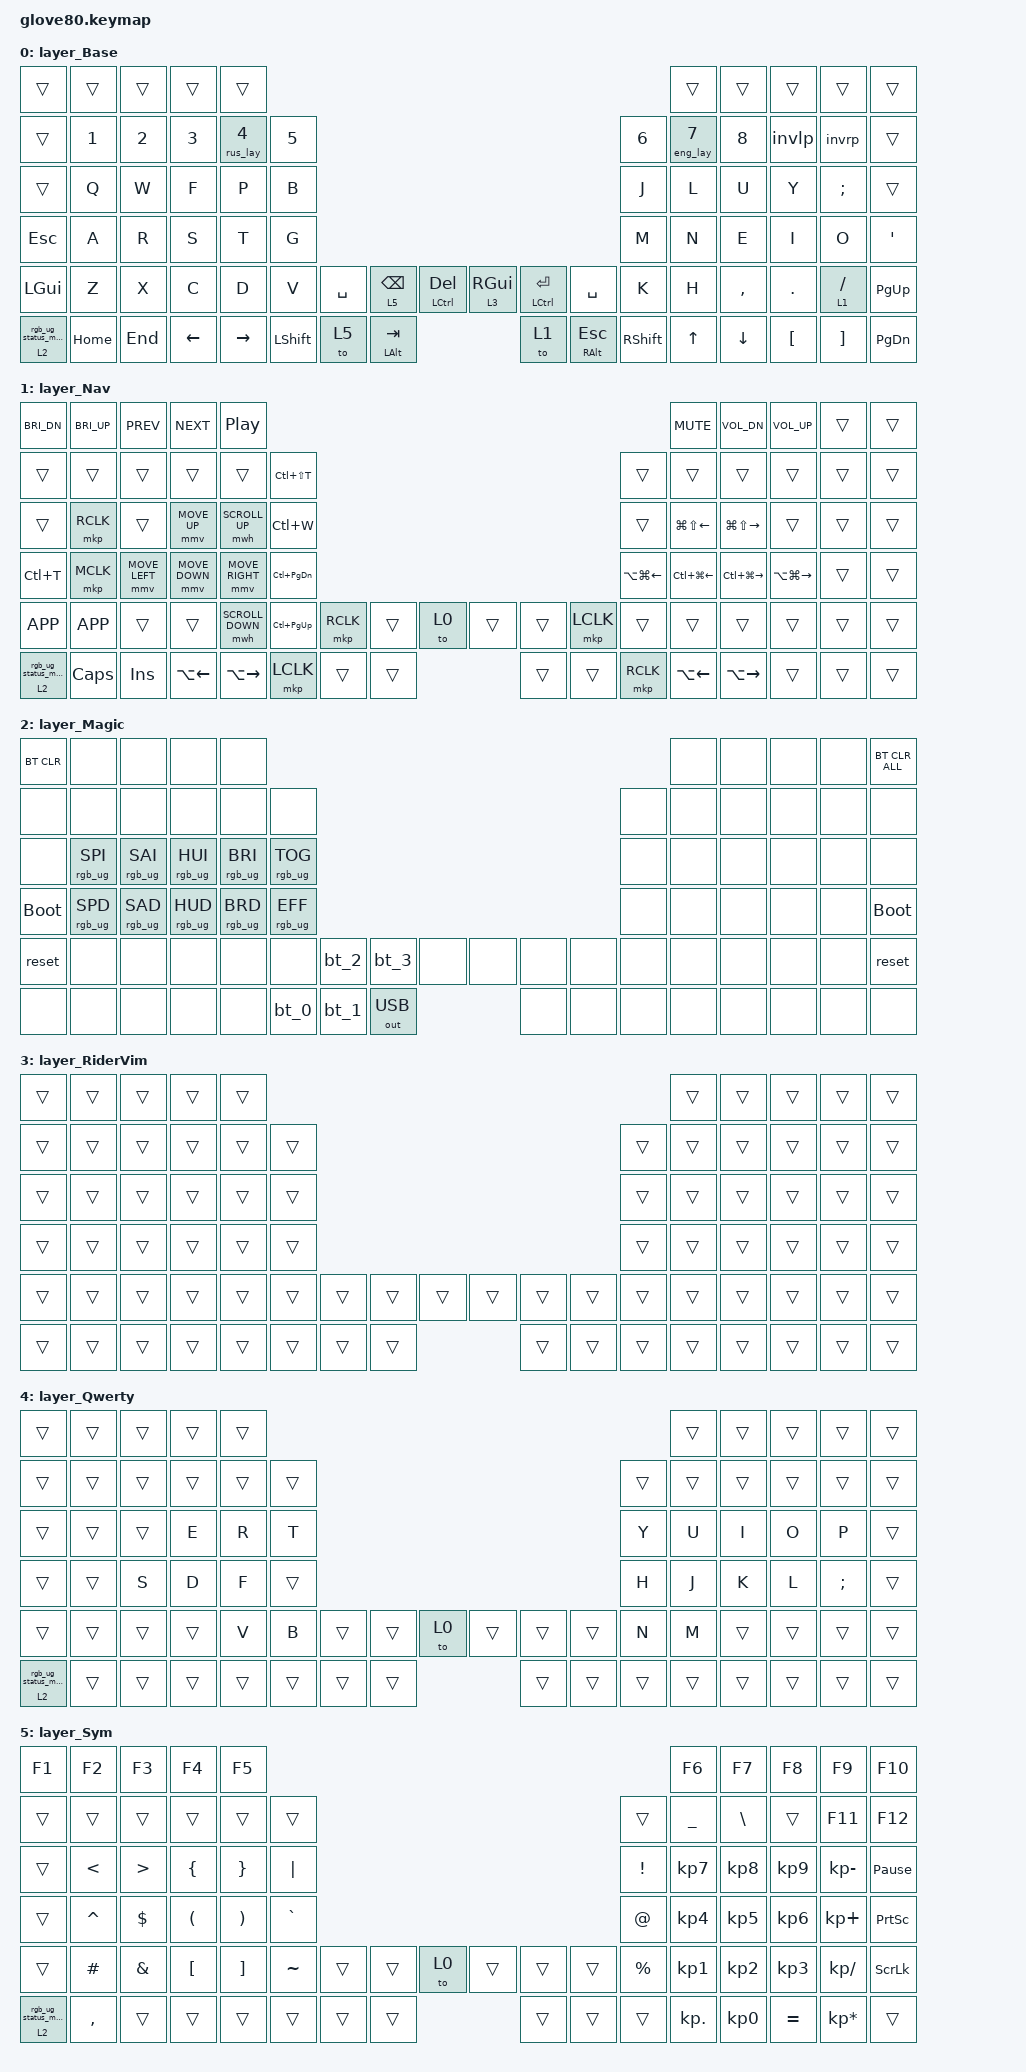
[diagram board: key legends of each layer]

/*
 * Copyright (c) 2020 The ZMK Contributors
 * Copyright (c) 2022 Innaworks Development Limited, trading as MoErgo
 *
 * SPDX-License-Identifier: MIT
 */


/* THIS FILE WAS GENERATED BY GLOVE80 LAYOUT EDITOR
 *
 * This file was generated automatically. You may or may not want to
 * edit it directly.
 */

#include <behaviors.dtsi>
/* Include all behaviour includes needed by system behaviors/macros */
#include <dt-bindings/zmk/outputs.h>

/* Include behaviour includes needed by key binds - automatically generated */
#include <dt-bindings/zmk/keys.h>
#include <dt-bindings/zmk/bt.h>
#include <dt-bindings/zmk/rgb.h>
#include <dt-bindings/zmk/outputs.h>
#include <dt-bindings/zmk/mouse.h>

&mmv {
    acceleration-exponent = <1>;      // 1
    time-to-max-speed-ms = <400>;     // 300
    delay-ms = <0>;                   // 0
};

&mwh {
    acceleration-exponent = <1>;      // 0
    time-to-max-speed-ms = <40>;      // 300
    delay-ms = <0>;                   // 0
};

#define U_MOUSE_MOVE_MAX 1200       // 600
#define U_MOUSE_SCROLL_MAX 20       // 10

#undef MOVE_UP
#undef MOVE_DOWN
#undef MOVE_LEFT
#undef MOVE_RIGHT
#define MOVE_UP MOVE_VERT(-U_MOUSE_MOVE_MAX)
#define MOVE_DOWN MOVE_VERT(U_MOUSE_MOVE_MAX)
#define MOVE_LEFT MOVE_HOR(-U_MOUSE_MOVE_MAX)
#define MOVE_RIGHT MOVE_HOR(U_MOUSE_MOVE_MAX)

#undef SCROLL_UP
#undef SCROLL_DOWN
#undef SCROLL_LEFT
#undef SCROLL_RIGHT
#define SCROLL_UP SCROLL_VERT(U_MOUSE_SCROLL_MAX)
#define SCROLL_DOWN SCROLL_VERT(-U_MOUSE_SCROLL_MAX)
#define SCROLL_LEFT SCROLL_HOR(-U_MOUSE_SCROLL_MAX)
#define SCROLL_RIGHT SCROLL_HOR(U_MOUSE_SCROLL_MAX)

/ {
    /* Glove80 system behavior & macros */
    behaviors {
        // For the "layer" key, it'd nice to be able to use it as either a shift or a toggle.
        // Configure it as a tap dance, so the first tap (or hold) is a &mo and the second tap is a &to
        lower: tap_dance_0 {
            compatible = "zmk,behavior-tap-dance";
            label = "LAYER_TAP_DANCE";
            #binding-cells = <0>;
            tapping-term-ms = <200>;
            bindings = <&mo 1>, <&to 1>;
        };
    };

    macros {
        rgb_ug_status_macro: rgb_ug_status_macro_0 {
            label = "RGB_UG_STATUS";
            compatible = "zmk,behavior-macro";
            #binding-cells = <0>;
            bindings
                = <&rgb_ug RGB_STATUS>;
        };
    };

    macros {
        bt_0: bt_profile_macro_0 {
            label = "BT_0";
            compatible = "zmk,behavior-macro";
            #binding-cells = <0>;
            bindings
                = <&out OUT_BLE>,
                  <&bt BT_SEL 0>;
        };
    };

    macros {
        bt_1: bt_profile_macro_1 {
            label = "BT_1";
            compatible = "zmk,behavior-macro";
            #binding-cells = <0>;
            bindings
                = <&out OUT_BLE>,
                  <&bt BT_SEL 1>;
        };
    };

    macros {
        bt_2: bt_profile_macro_2 {
            label = "BT_2";
            compatible = "zmk,behavior-macro";
            #binding-cells = <0>;
            bindings
                = <&out OUT_BLE>,
                  <&bt BT_SEL 2>;
        };
    };

    macros {
        bt_3: bt_profile_macro_3 {
            label = "BT_3";
            compatible = "zmk,behavior-macro";
            #binding-cells = <0>;
            bindings
                = <&out OUT_BLE>,
                  <&bt BT_SEL 3>;
        };
    };

    magic: magic_hold_tap {
        compatible = "zmk,behavior-hold-tap";
        label = "MAGIC_HOLD_TAP";
        #binding-cells = <2>;
        flavor = "tap-preferred";
        tapping-term-ms = <200>;
        bindings = <&mo>, <&rgb_ug_status_macro>;
    };

    /* Custom Defined Behaviors */
behaviors {
    invlp: invert_leftpar {
        compatible = "zmk,behavior-mod-morph";
        label = "INVERT_LEFTP";
        #binding-cells = <0>;
        bindings = <&kp LEFT_PARENTHESIS>, <&kp KP_N9>;
        mods = <(MOD_LSFT|MOD_RSFT)>;
    };
    invrp: invert_rightpar {
        compatible = "zmk,behavior-mod-morph";
        label = "INVERT_RIGHTP";
        #binding-cells = <0>;
        bindings = <&kp RIGHT_PARENTHESIS>, <&kp KP_N0>;
        mods = <(MOD_LSFT|MOD_RSFT)>;
    };
rlt: rus-layout-tap {
    compatible = "zmk,behavior-hold-tap";
    label = "RUS_LAYOUT_TAP";
    #binding-cells = <2>;
    flavor = "tap-preferred";
    tapping-term-ms = <200>;
    quick-tap-ms = <125>;
    bindings = <&rus_lay>, <&kp>;
};
elt: eng-layout-tap {
    compatible = "zmk,behavior-hold-tap";
    label = "ENG_LAYOUT_TAP";
    #binding-cells = <2>;
    flavor = "tap-preferred";
    tapping-term-ms = <200>;
    quick-tap-ms = <125>;
    bindings = <&eng_lay>, <&kp>;
};
hpt: hold-pref-tap {
    compatible = "zmk,behavior-hold-tap";
    label = "HOLD_PREF_TAP";
    #binding-cells = <2>;
    flavor = "hold-preferred";
    tapping-term-ms = <200>;
    bindings = <&kp>, <&kp>;
};
};

macros {
    rus_lay: rus_lay {
        label = "ZM_rus_layout";
        compatible = "zmk,behavior-macro";
        #binding-cells = <0>;
        bindings
            = <&to 4>
            , <&kp LC(LS(NUMBER_2))>
            ;
    };
    eng_lay: eng_lay {
        label = "ZM_eng_layout";
        compatible = "zmk,behavior-macro";
        #binding-cells = <0>;
        bindings
            = <&to 0>
            , <&kp LC(LS(NUMBER_1))>
            ;
    };
};


    /* Automatically generated keymap */
    keymap {
        compatible = "zmk,keymap";


        layer_Base {
            bindings = <
     &trans    &trans   &trans    &trans           &trans                                                                                                       &trans     &trans    &trans      &trans     &trans
     &trans    &kp N1   &kp N2    &kp N3  &rlt 0 NUMBER_4  &kp N5                                                                              &kp N6  &elt 0 NUMBER_7     &kp N8    &invlp      &invrp     &trans
     &trans     &kp Q    &kp W     &kp F            &kp P   &kp B                                                                               &kp J            &kp L      &kp U     &kp Y    &kp SEMI     &trans
    &kp ESC     &kp A    &kp R     &kp S            &kp T   &kp G                                                                               &kp M            &kp N      &kp E     &kp I       &kp O    &kp SQT
   &kp LGUI     &kp Z    &kp X     &kp C            &kp D   &kp V  &kp SPACE  &lt 5 BSPC  &mt LCTRL DEL  &lt 3 RGUI  &mt LCTRL RET  &kp SPACE   &kp K            &kp H  &kp COMMA   &kp DOT  &lt 1 FSLH  &kp PG_UP
 &magic 2 0  &kp HOME  &kp END  &kp LEFT        &kp RIGHT          &kp LSHFT       &to 5   &mt LALT TAB       &to 1   &mt RALT ESC  &kp RSHFT                   &kp UP   &kp DOWN  &kp LBKT    &kp RBKT  &kp PG_DN
            >;
        };

        layer_Nav {
            bindings = <
 &kp C_BRI_DN  &kp C_BRI_UP      &kp C_PREV          &kp C_NEXT             &kp C_PP                                                                                                               &kp C_MUTE             &kp C_VOL_DN             &kp C_VOL_UP  &trans  &trans
       &trans        &trans          &trans              &trans               &trans      &kp LC(LS(T))                                                                        &trans                  &trans                   &trans                   &trans  &trans  &trans
       &trans     &mkp RCLK          &trans        &mmv MOVE_UP       &mwh SCROLL_UP          &kp LC(W)                                                                        &trans  &kp LG(LS(LEFT_ARROW))  &kp LG(LS(RIGHT_ARROW))                   &trans  &trans  &trans
    &kp LC(T)     &mkp MCLK  &mmv MOVE_LEFT      &mmv MOVE_DOWN      &mmv MOVE_RIGHT  &kp LC(PAGE_DOWN)                                                        &kp LA(LG(LEFT_ARROW))  &kp LC(LG(LEFT_ARROW))  &kp LC(LG(RIGHT_ARROW))  &kp LA(LG(RIGHT_ARROW))  &trans  &trans
    &kp K_APP     &kp K_APP          &trans              &trans     &mwh SCROLL_DOWN    &kp LC(PAGE_UP)  &mkp RCLK  &trans   &to 0  &trans  &trans  &mkp LCLK                  &trans                  &trans                   &trans                   &trans  &trans  &trans
   &magic 2 0      &kp CAPS         &kp INS  &kp LA(LEFT_ARROW)  &kp LA(RIGHT_ARROW)                     &mkp LCLK  &trans  &trans  &trans  &trans  &mkp RCLK                              &kp LA(LEFT_ARROW)      &kp LA(RIGHT_ARROW)                   &trans  &trans  &trans
            >;
        };

        layer_Magic {
            bindings = <
  &bt BT_CLR            &none            &none            &none            &none                                                                                  &none   &none   &none   &none  &bt BT_CLR_ALL
       &none            &none            &none            &none            &none            &none                                                         &none   &none   &none   &none   &none           &none
       &none  &rgb_ug RGB_SPI  &rgb_ug RGB_SAI  &rgb_ug RGB_HUI  &rgb_ug RGB_BRI  &rgb_ug RGB_TOG                                                         &none   &none   &none   &none   &none           &none
 &bootloader  &rgb_ug RGB_SPD  &rgb_ug RGB_SAD  &rgb_ug RGB_HUD  &rgb_ug RGB_BRD  &rgb_ug RGB_EFF                                                         &none   &none   &none   &none   &none     &bootloader
      &reset            &none            &none            &none            &none            &none   &bt_2   &bt_3         &none   &none   &none   &none   &none   &none   &none   &none   &none          &reset
       &none            &none            &none            &none            &none                    &bt_0   &bt_1  &out OUT_USB   &none   &none   &none           &none   &none   &none   &none           &none
            >;
        };

        layer_RiderVim {
            bindings = <
 &trans  &trans  &trans  &trans  &trans                                                                  &trans  &trans  &trans  &trans  &trans
 &trans  &trans  &trans  &trans  &trans  &trans                                                  &trans  &trans  &trans  &trans  &trans  &trans
 &trans  &trans  &trans  &trans  &trans  &trans                                                  &trans  &trans  &trans  &trans  &trans  &trans
 &trans  &trans  &trans  &trans  &trans  &trans                                                  &trans  &trans  &trans  &trans  &trans  &trans
 &trans  &trans  &trans  &trans  &trans  &trans  &trans  &trans  &trans  &trans  &trans  &trans  &trans  &trans  &trans  &trans  &trans  &trans
 &trans  &trans  &trans  &trans  &trans          &trans  &trans  &trans  &trans  &trans  &trans          &trans  &trans  &trans  &trans  &trans
            >;
        };

        layer_Qwerty {
            bindings = <
     &trans  &trans  &trans  &trans  &trans                                                                  &trans  &trans  &trans    &trans  &trans
     &trans  &trans  &trans  &trans  &trans  &trans                                                  &trans  &trans  &trans  &trans    &trans  &trans
     &trans  &trans  &trans   &kp E   &kp R   &kp T                                                   &kp Y   &kp U   &kp I   &kp O     &kp P  &trans
     &trans  &trans   &kp S   &kp D   &kp F  &trans                                                   &kp H   &kp J   &kp K   &kp L  &kp SEMI  &trans
     &trans  &trans  &trans  &trans   &kp V   &kp B  &trans  &trans   &to 0  &trans  &trans  &trans   &kp N   &kp M  &trans  &trans    &trans  &trans
 &magic 2 0  &trans  &trans  &trans  &trans          &trans  &trans  &trans  &trans  &trans  &trans          &trans  &trans  &trans    &trans  &trans
            >;
        };

        layer_Sym {
            bindings = <
     &kp F1     &kp F2    &kp F3    &kp F4    &kp F5                                                                            &kp F6     &kp F7     &kp F8           &kp F9          &kp F10
     &trans     &trans    &trans    &trans    &trans     &trans                                                     &trans   &kp UNDER   &kp BSLH     &trans          &kp F11          &kp F12
     &trans     &kp LT    &kp GT  &kp LBRC  &kp RBRC   &kp PIPE                                                   &kp EXCL   &kp KP_N7  &kp KP_N8  &kp KP_N9     &kp KP_MINUS  &kp PAUSE_BREAK
     &trans  &kp CARET  &kp DLLR  &kp LPAR  &kp RPAR  &kp GRAVE                                                     &kp AT   &kp KP_N4  &kp KP_N5  &kp KP_N6      &kp KP_PLUS        &kp PSCRN
     &trans   &kp HASH  &kp AMPS  &kp LBKT  &kp RBKT  &kp TILDE  &trans  &trans   &to 0  &trans  &trans  &trans  &kp PRCNT   &kp KP_N1  &kp KP_N2  &kp KP_N3     &kp KP_SLASH         &kp SLCK
 &magic 2 0  &kp COMMA    &trans    &trans    &trans             &trans  &trans  &trans  &trans  &trans  &trans             &kp KP_DOT  &kp KP_N0  &kp EQUAL  &kp KP_MULTIPLY           &trans
            >;
        };

    };
};

